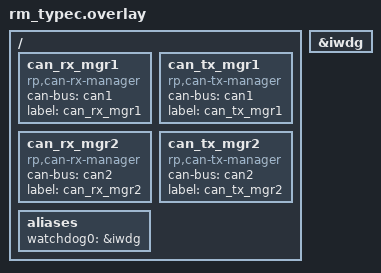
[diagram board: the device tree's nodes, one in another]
/* This file will automatic applyed when using rm_typec board */

/ {

    can_rx_mgr1: can_rx_mgr1 {
        compatible = "rp,can-rx-manager";
        status = "okay";
        can-bus = <&can1>;
        label = "can_rx_mgr1";
    };

    can_tx_mgr1: can_tx_mgr1 {
        compatible = "rp,can-tx-manager";
        status = "okay";
        can-bus = <&can1>;
        label = "can_tx_mgr1";
    };
    can_rx_mgr2: can_rx_mgr2 {
            compatible = "rp,can-rx-manager";
            status = "okay";
            can-bus = <&can2>;
            label = "can_rx_mgr2";
        };
    can_tx_mgr2: can_tx_mgr2 {
        compatible = "rp,can-tx-manager";
        status = "okay";
        can-bus = <&can2>;
        label = "can_tx_mgr2";
    };

    aliases {
        watchdog0 = &iwdg;  /* 将 watchdog0 指向 IWDG 硬件 */
    };
};

&iwdg {
    status = "okay"; /* 启用独立看门狗 IWDG */
};
